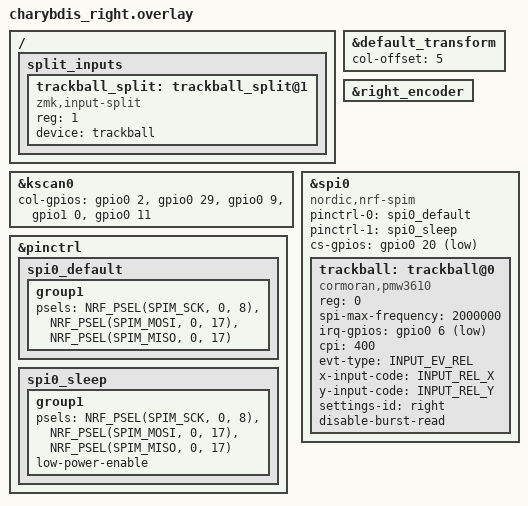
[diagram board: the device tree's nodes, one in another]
/*
 * Copyright (c) 2020 ZMK Contributors
 *
 * SPDX-License-Identifier: MIT
 */
 
#include "charybdis.dtsi"
#include <dt-bindings/input/input-event-codes.h>

&default_transform {
    col-offset = <5>;
}; 

&kscan0 {
	col-gpios
		= <&gpio0 2 (GPIO_ACTIVE_HIGH | GPIO_PULL_DOWN)>
		, <&gpio0 29 (GPIO_ACTIVE_HIGH | GPIO_PULL_DOWN)>
		, <&gpio0 9 (GPIO_ACTIVE_HIGH | GPIO_PULL_DOWN)>
		, <&gpio1 0  (GPIO_ACTIVE_HIGH | GPIO_PULL_DOWN)>
		, <&gpio0 11 (GPIO_ACTIVE_HIGH | GPIO_PULL_DOWN)>
		
		;
};
&right_encoder {
    status = "okay";
};

// trackball bus
&pinctrl {
    spi0_default: spi0_default {
        group1 {
            psels = <NRF_PSEL(SPIM_SCK, 0, 8)>,
                <NRF_PSEL(SPIM_MOSI, 0, 17)>,
                <NRF_PSEL(SPIM_MISO, 0, 17)>;
        };
    };

    spi0_sleep: spi0_sleep {
        group1 {
            psels = <NRF_PSEL(SPIM_SCK, 0, 8)>,
                <NRF_PSEL(SPIM_MOSI, 0, 17)>,
                <NRF_PSEL(SPIM_MISO, 0, 17)>;
            low-power-enable;
        };
    };
};

&spi0 {
    status = "okay";
    compatible = "nordic,nrf-spim";
    pinctrl-0 = <&spi0_default>;
    pinctrl-1 = <&spi0_sleep>;
    pinctrl-names = "default", "sleep";
    cs-gpios = <&gpio0 20 GPIO_ACTIVE_LOW>;

    trackball: trackball@0 {
        status = "okay";
        compatible = "cormoran,pmw3610";
        reg = <0>;
        spi-max-frequency = <2000000>;
        irq-gpios = <&gpio0 6 (GPIO_ACTIVE_LOW | GPIO_PULL_UP)>;
        cpi = <400>;
        evt-type = <INPUT_EV_REL>;
        x-input-code = <INPUT_REL_X>;
        y-input-code = <INPUT_REL_Y>;
        settings-id = "right";
        disable-burst-read;
    };
};

/ {
    split_inputs {
        #address-cells = <1>;
        #size-cells = <0>;

        // ZMK v0.3 uses zero as the "not discovered yet" input-slot sentinel.
        trackball_split: trackball_split@1 {
            compatible = "zmk,input-split";
            reg = <1>;
            device = <&trackball>;
        };
    };
};


